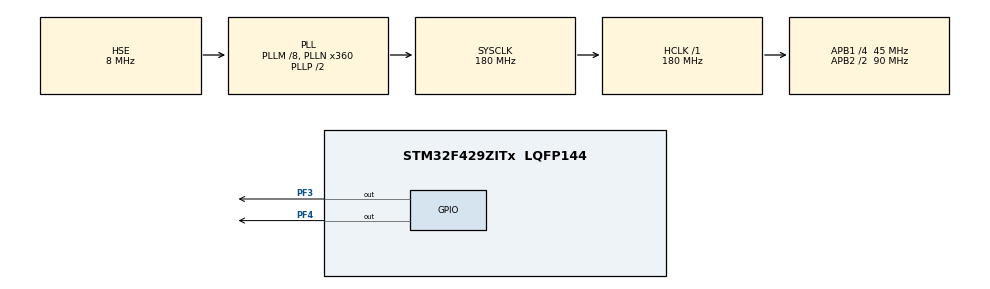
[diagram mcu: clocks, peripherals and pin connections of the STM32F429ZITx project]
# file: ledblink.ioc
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Mcu.Family=STM32F4
Mcu.Name=STM32F429ZITx
Mcu.Package=LQFP144
NVIC.PriorityGroup=NVIC_PRIORITYGROUP_4
NVIC.TIM6_DAC_IRQn=true\:0\:0\:false\:false\:true\:true\:true\:true
NVIC.TIM7_IRQn=true\:0\:0\:false\:false\:true\:true\:true\:true
PA13.Mode=Serial_Wire
PA13.Signal=SYS_JTMS-SWDIO
PA14.Mode=Serial_Wire
PA14.Signal=SYS_JTCK-SWCLK
PF3.GPIO_Speed=GPIO_SPEED_FREQ_HIGH
PF3.Signal=GPIO_Output
PF4.GPIO_Speed=GPIO_SPEED_FREQ_HIGH
PF4.Signal=GPIO_Output
PH0/OSC_IN.Mode=HSE-External-Oscillator
PH0/OSC_IN.Signal=RCC_OSC_IN
PH1/OSC_OUT.Mode=HSE-External-Oscillator
PH1/OSC_OUT.Signal=RCC_OSC_OUT
ProjectManager.HeapSize=0x200
ProjectManager.StackSize=0x400
ProjectManager.TargetToolchain=STM32CubeIDE
RCC.48MHZClocksFreq_Value=90000000
RCC.AHBFreq_Value=180000000
RCC.APB1CLKDivider=RCC_HCLK_DIV4
RCC.APB1Freq_Value=45000000
RCC.APB1TimFreq_Value=90000000
RCC.APB2CLKDivider=RCC_HCLK_DIV2
RCC.APB2Freq_Value=90000000
RCC.APB2TimFreq_Value=180000000
RCC.CortexFreq_Value=180000000
RCC.HCLKFreq_Value=180000000
RCC.HSE_VALUE=8000000
RCC.HSI_VALUE=16000000
RCC.LSE_VALUE=32768
RCC.PLLM=8
RCC.PLLN=360
RCC.PLLSourceVirtual=RCC_PLLSOURCE_HSE
RCC.SYSCLKFreq_VALUE=180000000
RCC.SYSCLKSource=RCC_SYSCLKSOURCE_PLLCLK
RCC.VCOOutputFreq_Value=360000000
TIM6.Period=4999
TIM6.Prescaler=8999
TIM7.Period=7499
TIM7.Prescaler=8999
VP_TIM6_VS_ClockSourceINT.Mode=Enable_Timer
VP_TIM7_VS_ClockSourceINT.Mode=Enable_Timer
board=custom

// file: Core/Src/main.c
/* USER CODE BEGIN Header */
/**
  ******************************************************************************
  * @file           : main.c
  * @brief          : Main program body
  ******************************************************************************
  * @attention
  *
  * Copyright (c) 2025 STMicroelectronics.
  * All rights reserved.
  *
  * This software is licensed under terms that can be found in the LICENSE file
  * in the root directory of this software component.
  * If no LICENSE file comes with this software, it is provided AS-IS.
  *
  ******************************************************************************
  */
/* USER CODE END Header */
#include "main.h"

TIM_HandleTypeDef htim6;
TIM_HandleTypeDef htim7;

void SystemClock_Config(void);
static void MX_GPIO_Init(void);
static void MX_TIM6_Init(void);
static void MX_TIM7_Init(void);

/* USER CODE BEGIN 0 */
// Callback cho TIM6 & TIM7
void HAL_TIM_PeriodElapsedCallback(TIM_HandleTypeDef *htim)
{
    if (htim->Instance == TIM6)
    {
        HAL_GPIO_TogglePin(GPIOF, GPIO_PIN_4); // LED3
    }
    else if (htim->Instance == TIM7)
    {
        HAL_GPIO_TogglePin(GPIOF, GPIO_PIN_3); // LED4
    }
}
/* USER CODE END 0 */

int main(void)
{
  HAL_Init();
  SystemClock_Config();
  MX_GPIO_Init();
  MX_TIM6_Init();
  MX_TIM7_Init();

  /* USER CODE BEGIN 2 */
  HAL_TIM_Base_Start_IT(&htim6);   // LED3 chớp 1s
  HAL_TIM_Base_Start_IT(&htim7);   // LED4 chớp 750ms
  /* USER CODE END 2 */

  while (1)
  {
    // Main loop không cần làm gì
  }
}

void SystemClock_Config(void)
{
  RCC_OscInitTypeDef RCC_OscInitStruct = {0};
  RCC_ClkInitTypeDef RCC_ClkInitStruct = {0};

  __HAL_RCC_PWR_CLK_ENABLE();
  __HAL_PWR_VOLTAGESCALING_CONFIG(PWR_REGULATOR_VOLTAGE_SCALE1);

  RCC_OscInitStruct.OscillatorType = RCC_OSCILLATORTYPE_HSE;
  RCC_OscInitStruct.HSEState = RCC_HSE_ON;
  RCC_OscInitStruct.PLL.PLLState = RCC_PLL_ON;
  RCC_OscInitStruct.PLL.PLLSource = RCC_PLLSOURCE_HSE;
  RCC_OscInitStruct.PLL.PLLM = 8;
  RCC_OscInitStruct.PLL.PLLN = 360;
  RCC_OscInitStruct.PLL.PLLP = RCC_PLLP_DIV2;
  RCC_OscInitStruct.PLL.PLLQ = 4;
  if (HAL_RCC_OscConfig(&RCC_OscInitStruct) != HAL_OK) { Error_Handler(); }

  if (HAL_PWREx_EnableOverDrive() != HAL_OK) { Error_Handler(); }

  RCC_ClkInitStruct.ClockType = RCC_CLOCKTYPE_HCLK|RCC_CLOCKTYPE_SYSCLK
                              |RCC_CLOCKTYPE_PCLK1|RCC_CLOCKTYPE_PCLK2;
  RCC_ClkInitStruct.SYSCLKSource = RCC_SYSCLKSOURCE_PLLCLK;
  RCC_ClkInitStruct.AHBCLKDivider = RCC_SYSCLK_DIV1;
  RCC_ClkInitStruct.APB1CLKDivider = RCC_HCLK_DIV4;
  RCC_ClkInitStruct.APB2CLKDivider = RCC_HCLK_DIV2;

  if (HAL_RCC_ClockConfig(&RCC_ClkInitStruct, FLASH_LATENCY_5) != HAL_OK) { Error_Handler(); }
}

/* TIM6 = LED3 1s */
static void MX_TIM6_Init(void)
{
  TIM_MasterConfigTypeDef sMasterConfig = {0};

  htim6.Instance = TIM6;
  htim6.Init.Prescaler = 8999;             // f_cnt = 10 kHz
  htim6.Init.CounterMode = TIM_COUNTERMODE_UP;
  htim6.Init.Period = 9999;                // 10,000 tick = 1s
  htim6.Init.AutoReloadPreload = TIM_AUTORELOAD_PRELOAD_DISABLE;
  if (HAL_TIM_Base_Init(&htim6) != HAL_OK) { Error_Handler(); }

  sMasterConfig.MasterOutputTrigger = TIM_TRGO_RESET;
  sMasterConfig.MasterSlaveMode = TIM_MASTERSLAVEMODE_DISABLE;
  if (HAL_TIMEx_MasterConfigSynchronization(&htim6, &sMasterConfig) != HAL_OK) { Error_Handler(); }
}

/* TIM7 = LED4 750ms */
static void MX_TIM7_Init(void)
{
  TIM_MasterConfigTypeDef sMasterConfig = {0};

  htim7.Instance = TIM7;
  htim7.Init.Prescaler = 8999;             // f_cnt = 10 kHz
  htim7.Init.CounterMode = TIM_COUNTERMODE_UP;
  htim7.Init.Period = 7499;                // 7,500 tick = 0.75s
  htim7.Init.AutoReloadPreload = TIM_AUTORELOAD_PRELOAD_DISABLE;
  if (HAL_TIM_Base_Init(&htim7) != HAL_OK) { Error_Handler(); }

  sMasterConfig.MasterOutputTrigger = TIM_TRGO_RESET;
  sMasterConfig.MasterSlaveMode = TIM_MASTERSLAVEMODE_DISABLE;
  if (HAL_TIMEx_MasterConfigSynchronization(&htim7, &sMasterConfig) != HAL_OK) { Error_Handler(); }
}

/* GPIO PF3 = LED4, PF4 = LED3 */
static void MX_GPIO_Init(void)
{
  GPIO_InitTypeDef GPIO_InitStruct = {0};

  __HAL_RCC_GPIOF_CLK_ENABLE();

  HAL_GPIO_WritePin(GPIOF, GPIO_PIN_3|GPIO_PIN_4, GPIO_PIN_RESET);

  GPIO_InitStruct.Pin = GPIO_PIN_3|GPIO_PIN_4;
  GPIO_InitStruct.Mode = GPIO_MODE_OUTPUT_PP;
  GPIO_InitStruct.Pull = GPIO_NOPULL;
  GPIO_InitStruct.Speed = GPIO_SPEED_FREQ_HIGH;
  HAL_GPIO_Init(GPIOF, &GPIO_InitStruct);
}

void Error_Handler(void)
{
  __disable_irq();
  while (1) {}
}
